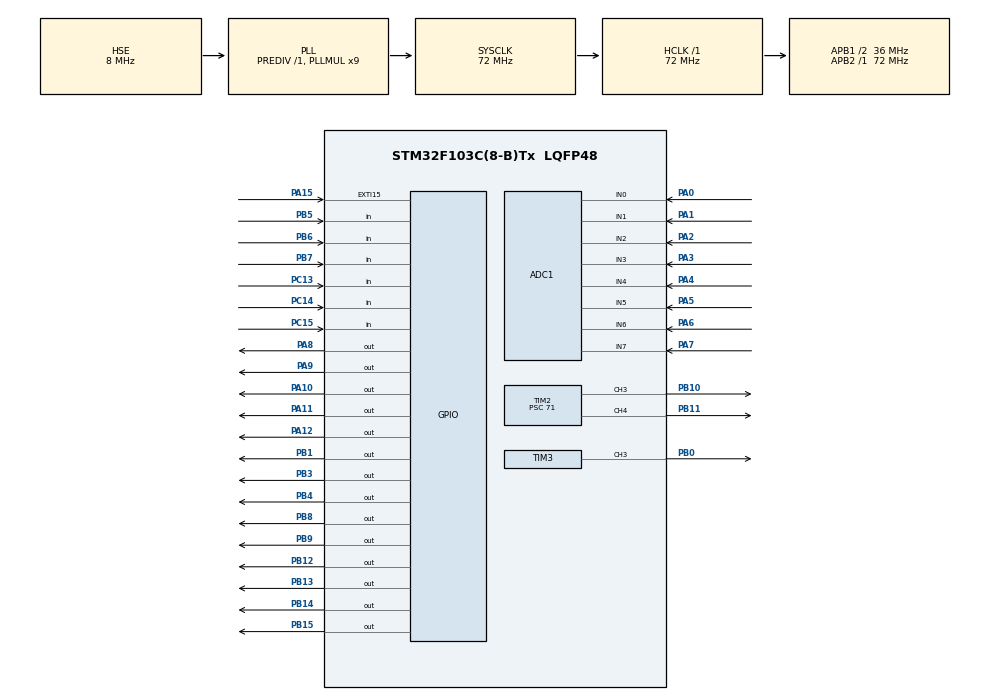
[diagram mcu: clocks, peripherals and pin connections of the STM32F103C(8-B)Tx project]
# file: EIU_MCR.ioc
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ADC1.Channel-0\#ChannelRegularConversion=ADC_CHANNEL_0
ADC1.Channel-1\#ChannelRegularConversion=ADC_CHANNEL_1
ADC1.Channel-2\#ChannelRegularConversion=ADC_CHANNEL_2
ADC1.Channel-3\#ChannelRegularConversion=ADC_CHANNEL_3
ADC1.Channel-4\#ChannelRegularConversion=ADC_CHANNEL_4
ADC1.Channel-5\#ChannelRegularConversion=ADC_CHANNEL_5
ADC1.Channel-6\#ChannelRegularConversion=ADC_CHANNEL_6
ADC1.Channel-7\#ChannelRegularConversion=ADC_CHANNEL_7
ADC1.ContinuousConvMode=ENABLE
ADC1.NbrOfConversion=8
ADC1.NbrOfConversionFlag=1
ADC1.Rank-0\#ChannelRegularConversion=1
ADC1.Rank-1\#ChannelRegularConversion=2
ADC1.Rank-2\#ChannelRegularConversion=3
ADC1.Rank-3\#ChannelRegularConversion=4
ADC1.Rank-4\#ChannelRegularConversion=5
ADC1.Rank-5\#ChannelRegularConversion=6
ADC1.Rank-6\#ChannelRegularConversion=7
ADC1.Rank-7\#ChannelRegularConversion=8
ADC1.SamplingTime-0\#ChannelRegularConversion=ADC_SAMPLETIME_239CYCLES_5
ADC1.SamplingTime-1\#ChannelRegularConversion=ADC_SAMPLETIME_239CYCLES_5
ADC1.SamplingTime-2\#ChannelRegularConversion=ADC_SAMPLETIME_239CYCLES_5
ADC1.SamplingTime-3\#ChannelRegularConversion=ADC_SAMPLETIME_239CYCLES_5
ADC1.SamplingTime-4\#ChannelRegularConversion=ADC_SAMPLETIME_239CYCLES_5
ADC1.SamplingTime-5\#ChannelRegularConversion=ADC_SAMPLETIME_239CYCLES_5
ADC1.SamplingTime-6\#ChannelRegularConversion=ADC_SAMPLETIME_239CYCLES_5
ADC1.SamplingTime-7\#ChannelRegularConversion=ADC_SAMPLETIME_239CYCLES_5
ADC1.master=1
Dma.ADC1.0.Direction=DMA_PERIPH_TO_MEMORY
Dma.ADC1.0.Instance=DMA1_Channel1
Dma.ADC1.0.MemDataAlignment=DMA_MDATAALIGN_HALFWORD
Dma.ADC1.0.MemInc=DMA_MINC_ENABLE
Dma.ADC1.0.Mode=DMA_CIRCULAR
Dma.ADC1.0.PeriphDataAlignment=DMA_PDATAALIGN_HALFWORD
Dma.ADC1.0.PeriphInc=DMA_PINC_DISABLE
Dma.ADC1.0.Priority=DMA_PRIORITY_MEDIUM
Dma.Request0=ADC1
Mcu.Family=STM32F1
Mcu.Name=STM32F103C(8-B)Tx
Mcu.Package=LQFP48
NVIC.DMA1_Channel1_IRQn=true\:0\:0\:false\:false\:true\:false\:true\:true
NVIC.EXTI15_10_IRQn=true\:1\:0\:true\:false\:true\:true\:true\:true
NVIC.PriorityGroup=NVIC_PRIORITYGROUP_4
NVIC.TIM1_UP_IRQn=true\:1\:0\:true\:false\:true\:true\:true\:true
PA0-WKUP.GPIO_Mode=GPIO_MODE_ANALOG
PA0-WKUP.Signal=ADCx_IN0
PA1.GPIO_Mode=GPIO_MODE_ANALOG
PA1.Signal=ADCx_IN1
PA10.GPIO_ModeDefaultOutputPP=GPIO_MODE_OUTPUT_PP
PA10.GPIO_Speed=GPIO_SPEED_FREQ_MEDIUM
PA10.PinState=GPIO_PIN_RESET
PA10.Signal=GPIO_Output
PA11.GPIO_Speed=GPIO_SPEED_FREQ_MEDIUM
PA11.Signal=GPIO_Output
PA12.GPIO_ModeDefaultOutputPP=GPIO_MODE_OUTPUT_PP
PA12.GPIO_PuPd=GPIO_NOPULL
PA12.Signal=GPIO_Output
PA13.Mode=Serial_Wire
PA13.Signal=SYS_JTMS-SWDIO
PA14.Mode=Serial_Wire
PA14.Signal=SYS_JTCK-SWCLK
PA15.GPIO_ModeDefaultEXTI=GPIO_MODE_IT_RISING_FALLING
PA15.GPIO_PuPd=GPIO_PULLUP
PA15.Signal=GPXTI15
PA2.GPIO_Mode=GPIO_MODE_ANALOG
PA2.Signal=ADCx_IN2
PA3.GPIO_Mode=GPIO_MODE_ANALOG
PA3.Signal=ADCx_IN3
PA4.GPIO_Mode=GPIO_MODE_ANALOG
PA4.Signal=ADCx_IN4
PA5.GPIO_Mode=GPIO_MODE_ANALOG
PA5.Signal=ADCx_IN5
PA6.GPIO_Mode=GPIO_MODE_ANALOG
PA6.Signal=ADCx_IN6
PA7.GPIO_Mode=GPIO_MODE_ANALOG
PA7.Signal=ADCx_IN7
PA8.GPIO_ModeDefaultOutputPP=GPIO_MODE_OUTPUT_PP
PA8.GPIO_PuPd=GPIO_NOPULL
PA8.GPIO_Speed=GPIO_SPEED_FREQ_LOW
PA8.PinState=GPIO_PIN_RESET
PA8.Signal=GPIO_Output
PA9.GPIO_PuPd=GPIO_NOPULL
PA9.Signal=GPIO_Output
PB0.Signal=S_TIM3_CH3
PB1.GPIO_Speed=GPIO_SPEED_FREQ_MEDIUM
PB1.Signal=GPIO_Output
PB10.Signal=S_TIM2_CH3
PB11.Signal=S_TIM2_CH4
PB12.GPIO_PuPd=GPIO_PULLDOWN
PB12.GPIO_Speed=GPIO_SPEED_FREQ_MEDIUM
PB12.Signal=GPIO_Output
PB13.GPIO_PuPd=GPIO_PULLDOWN
PB13.GPIO_Speed=GPIO_SPEED_FREQ_MEDIUM
PB13.PinState=GPIO_PIN_RESET
PB13.Signal=GPIO_Output
PB14.GPIO_PuPd=GPIO_PULLDOWN
PB14.GPIO_Speed=GPIO_SPEED_FREQ_MEDIUM
PB14.PinState=GPIO_PIN_RESET
PB14.Signal=GPIO_Output
PB15.GPIO_ModeDefaultOutputPP=GPIO_MODE_OUTPUT_PP
PB15.GPIO_PuPd=GPIO_PULLDOWN
PB15.Signal=GPIO_Output
PB3.GPIO_PuPd=GPIO_PULLDOWN
PB3.Signal=GPIO_Output
PB4.GPIO_Speed=GPIO_SPEED_FREQ_MEDIUM
PB4.Signal=GPIO_Output
PB5.GPIO_Mode=GPIO_MODE_INPUT
PB5.GPIO_PuPd=GPIO_PULLUP
PB5.Signal=GPIO_Input
PB6.GPIO_PuPd=GPIO_PULLUP
PB6.Signal=GPIO_Input
PB7.GPIO_PuPd=GPIO_PULLUP
PB7.Signal=GPIO_Input
PB8.GPIO_PuPd=GPIO_PULLDOWN
PB8.GPIO_Speed=GPIO_SPEED_FREQ_MEDIUM
PB8.PinState=GPIO_PIN_RESET
PB8.Signal=GPIO_Output
PB9.GPIO_PuPd=GPIO_PULLDOWN
PB9.GPIO_Speed=GPIO_SPEED_FREQ_MEDIUM
PB9.Signal=GPIO_Output
PC13-TAMPER-RTC.GPIO_Mode=GPIO_MODE_INPUT
PC13-TAMPER-RTC.GPIO_PuPd=GPIO_PULLUP
PC13-TAMPER-RTC.Signal=GPIO_Input
PC14-OSC32_IN.GPIO_Mode=GPIO_MODE_INPUT
PC14-OSC32_IN.GPIO_PuPd=GPIO_PULLUP
PC14-OSC32_IN.Signal=GPIO_Input
PC15-OSC32_OUT.GPIO_Mode=GPIO_MODE_INPUT
PC15-OSC32_OUT.GPIO_PuPd=GPIO_PULLUP
PC15-OSC32_OUT.Signal=GPIO_Input
PD0-OSC_IN.Mode=HSE-External-Oscillator
PD0-OSC_IN.Signal=RCC_OSC_IN
PD1-OSC_OUT.Mode=HSE-External-Oscillator
PD1-OSC_OUT.Signal=RCC_OSC_OUT
ProjectManager.HeapSize=0x200
ProjectManager.StackSize=0x400
ProjectManager.TargetToolchain=MDK-ARM V5.27
RCC.ADCPresc=RCC_ADCPCLK2_DIV6
RCC.AHBFreq_Value=72000000
RCC.APB1CLKDivider=RCC_HCLK_DIV2
RCC.APB1Freq_Value=36000000
RCC.APB1TimFreq_Value=72000000
RCC.APB2Freq_Value=72000000
RCC.APB2TimFreq_Value=72000000
RCC.HCLKFreq_Value=72000000
RCC.PLLMUL=RCC_PLL_MUL9
RCC.PLLSourceVirtual=RCC_PLLSOURCE_HSE
RCC.SYSCLKFreq_VALUE=72000000
RCC.SYSCLKSource=RCC_SYSCLKSOURCE_PLLCLK
RCC.USBFreq_Value=72000000
SH.ADCx_IN0.0=ADC1_IN0,IN0
SH.ADCx_IN1.0=ADC1_IN1,IN1
SH.ADCx_IN2.0=ADC1_IN2,IN2
SH.ADCx_IN3.0=ADC1_IN3,IN3
SH.ADCx_IN4.0=ADC1_IN4,IN4
SH.ADCx_IN5.0=ADC1_IN5,IN5
SH.ADCx_IN6.0=ADC1_IN6,IN6
SH.ADCx_IN7.0=ADC1_IN7,IN7
SH.S_TIM2_CH3.0=TIM2_CH3,PWM Generation3 CH3
SH.S_TIM2_CH4.0=TIM2_CH4,PWM Generation4 CH4
SH.S_TIM3_CH3.0=TIM3_CH3,PWM Generation3 CH3
TIM1.Prescaler=71
TIM2.Channel-PWM\ Generation3\ CH3=TIM_CHANNEL_3
TIM2.Channel-PWM\ Generation4\ CH4=TIM_CHANNEL_4
TIM2.OCFastMode_PWM-PWM\ Generation3\ CH3=TIM_OCFAST_ENABLE
TIM2.OCFastMode_PWM-PWM\ Generation4\ CH4=TIM_OCFAST_ENABLE
TIM2.Period=999
TIM2.Prescaler=71
TIM3.Channel-PWM\ Generation3\ CH3=TIM_CHANNEL_3
TIM3.CounterMode=TIM_COUNTERMODE_UP
TIM3.OCFastMode_PWM-PWM\ Generation3\ CH3=TIM_OCFAST_DISABLE
TIM3.Period=19999
TIM3.Prescaler=35
TIM4.Prescaler=71
VP_TIM1_VS_ClockSourceINT.Mode=Internal
VP_TIM4_VS_ClockSourceINT.Mode=Internal
board=custom

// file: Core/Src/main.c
/* USER CODE BEGIN Header */
/**
  ******************************************************************************
  * @file           : main.c
  * @brief          : Main program body
  ******************************************************************************
  * @attention
  *
  * <h2><center>&copy; Copyright (c) 2024 STMicroelectronics.
  * All rights reserved.</center></h2>
  *
  * This software component is licensed by ST under BSD 3-Clause license,
  * the "License"; You may not use this file except in compliance with the
  * License. You may obtain a copy of the License at:
  *                        opensource.org/licenses/BSD-3-Clause
  *
  ******************************************************************************
  */
/* USER CODE END Header */
#include "main.h"

/* USER CODE BEGIN Includes */
#include "robot.h"

/* USER CODE END Includes */

ADC_HandleTypeDef hadc1;
DMA_HandleTypeDef hdma_adc1;

TIM_HandleTypeDef htim1;
TIM_HandleTypeDef htim2;
TIM_HandleTypeDef htim3;
TIM_HandleTypeDef htim4;

void SystemClock_Config(void);
static void MX_GPIO_Init(void);
static void MX_DMA_Init(void);
static void MX_TIM3_Init(void);
static void MX_TIM2_Init(void);
static void MX_TIM1_Init(void);
static void MX_TIM4_Init(void);
static void MX_ADC1_Init(void);

/* USER CODE BEGIN 0 */
Robot MCR_robot;
TIM_HandleTypeDef *htim[] = {&htim1, &htim2, &htim3, &htim4};
void HAL_TIM_PeriodElapsedCallback(TIM_HandleTypeDef *htim)
{
 timer_handle(&MCR_robot);
}
/* USER CODE END 0 */

int main(void)

{

  /* MCU Configuration--------------------------------------------------------*/

  /* Reset of all peripherals, Initializes the Flash interface and the Systick. */
  HAL_Init();

  /* Configure the system clock */
  SystemClock_Config();

  /* Initialize all configured peripherals */
  MX_GPIO_Init();
  MX_DMA_Init();
  MX_TIM3_Init();
  MX_TIM2_Init();
  MX_TIM1_Init();
  MX_TIM4_Init();
  MX_ADC1_Init();
  /* USER CODE BEGIN 2 */
  robot_init(&MCR_robot, &hadc1, &hdma_adc1, htim);
	HAL_TIM_Base_Start_IT(&htim1);
  /* USER CODE END 2 */

  /* Infinite loop */
  while (1)
  {
    /* USER CODE BEGIN 3 */
		loop(&MCR_robot);
	  //handle(&servo, 0);
  }
  /* USER CODE END 3 */
}

void SystemClock_Config(void)
{
  RCC_OscInitTypeDef RCC_OscInitStruct = {0};
  RCC_ClkInitTypeDef RCC_ClkInitStruct = {0};
  RCC_PeriphCLKInitTypeDef PeriphClkInit = {0};

  /** Initializes the RCC Oscillators according to the specified parameters
  * in the RCC_OscInitTypeDef structure.
  */
  RCC_OscInitStruct.OscillatorType = RCC_OSCILLATORTYPE_HSE;
  RCC_OscInitStruct.HSEState = RCC_HSE_ON;
  RCC_OscInitStruct.HSEPredivValue = RCC_HSE_PREDIV_DIV1;
  RCC_OscInitStruct.HSIState = RCC_HSI_ON;
  RCC_OscInitStruct.PLL.PLLState = RCC_PLL_ON;
  RCC_OscInitStruct.PLL.PLLSource = RCC_PLLSOURCE_HSE;
  RCC_OscInitStruct.PLL.PLLMUL = RCC_PLL_MUL9;
  if (HAL_RCC_OscConfig(&RCC_OscInitStruct) != HAL_OK)
  {
    Error_Handler();
  }
  /** Initializes the CPU, AHB and APB buses clocks
  */
  RCC_ClkInitStruct.ClockType = RCC_CLOCKTYPE_HCLK|RCC_CLOCKTYPE_SYSCLK
                              |RCC_CLOCKTYPE_PCLK1|RCC_CLOCKTYPE_PCLK2;
  RCC_ClkInitStruct.SYSCLKSource = RCC_SYSCLKSOURCE_PLLCLK;
  RCC_ClkInitStruct.AHBCLKDivider = RCC_SYSCLK_DIV1;
  RCC_ClkInitStruct.APB1CLKDivider = RCC_HCLK_DIV2;
  RCC_ClkInitStruct.APB2CLKDivider = RCC_HCLK_DIV1;

  if (HAL_RCC_ClockConfig(&RCC_ClkInitStruct, FLASH_LATENCY_2) != HAL_OK)
  {
    Error_Handler();
  }
  PeriphClkInit.PeriphClockSelection = RCC_PERIPHCLK_ADC;
  PeriphClkInit.AdcClockSelection = RCC_ADCPCLK2_DIV6;
  if (HAL_RCCEx_PeriphCLKConfig(&PeriphClkInit) != HAL_OK)
  {
    Error_Handler();
  }
}

static void MX_ADC1_Init(void)
{

  ADC_ChannelConfTypeDef sConfig = {0};

  /** Common config
  */
  hadc1.Instance = ADC1;
  hadc1.Init.ScanConvMode = ADC_SCAN_ENABLE;
  hadc1.Init.ContinuousConvMode = ENABLE;
  hadc1.Init.DiscontinuousConvMode = DISABLE;
  hadc1.Init.ExternalTrigConv = ADC_SOFTWARE_START;
  hadc1.Init.DataAlign = ADC_DATAALIGN_RIGHT;
  hadc1.Init.NbrOfConversion = 8;
  if (HAL_ADC_Init(&hadc1) != HAL_OK)
  {
    Error_Handler();
  }
  /** Configure Regular Channel
  */
  sConfig.Channel = ADC_CHANNEL_0;
  sConfig.Rank = ADC_REGULAR_RANK_1;
  sConfig.SamplingTime = ADC_SAMPLETIME_239CYCLES_5;
  if (HAL_ADC_ConfigChannel(&hadc1, &sConfig) != HAL_OK)
  {
    Error_Handler();
  }
  /** Configure Regular Channel
  */
  sConfig.Channel = ADC_CHANNEL_1;
  sConfig.Rank = ADC_REGULAR_RANK_2;
  if (HAL_ADC_ConfigChannel(&hadc1, &sConfig) != HAL_OK)
  {
    Error_Handler();
  }
  /** Configure Regular Channel
  */
  sConfig.Channel = ADC_CHANNEL_2;
  sConfig.Rank = ADC_REGULAR_RANK_3;
  if (HAL_ADC_ConfigChannel(&hadc1, &sConfig) != HAL_OK)
  {
    Error_Handler();
  }
  /** Configure Regular Channel
  */
  sConfig.Channel = ADC_CHANNEL_3;
  sConfig.Rank = ADC_REGULAR_RANK_4;
  if (HAL_ADC_ConfigChannel(&hadc1, &sConfig) != HAL_OK)
  {
    Error_Handler();
  }
  /** Configure Regular Channel
  */
  sConfig.Channel = ADC_CHANNEL_4;
  sConfig.Rank = ADC_REGULAR_RANK_5;
  if (HAL_ADC_ConfigChannel(&hadc1, &sConfig) != HAL_OK)
  {
    Error_Handler();
  }
  /** Configure Regular Channel
  */
  sConfig.Channel = ADC_CHANNEL_5;
  sConfig.Rank = ADC_REGULAR_RANK_6;
  if (HAL_ADC_ConfigChannel(&hadc1, &sConfig) != HAL_OK)
  {
    Error_Handler();
  }
  /** Configure Regular Channel
  */
  sConfig.Channel = ADC_CHANNEL_6;
  sConfig.Rank = ADC_REGULAR_RANK_7;
  if (HAL_ADC_ConfigChannel(&hadc1, &sConfig) != HAL_OK)
  {
    Error_Handler();
  }
  /** Configure Regular Channel
  */
  sConfig.Channel = ADC_CHANNEL_7;
  sConfig.Rank = ADC_REGULAR_RANK_8;
  if (HAL_ADC_ConfigChannel(&hadc1, &sConfig) != HAL_OK)
  {
    Error_Handler();
  }

}

static void MX_TIM1_Init(void)
{

  TIM_ClockConfigTypeDef sClockSourceConfig = {0};
  TIM_MasterConfigTypeDef sMasterConfig = {0};

  htim1.Instance = TIM1;
  htim1.Init.Prescaler = 71;
  htim1.Init.CounterMode = TIM_COUNTERMODE_UP;
  htim1.Init.Period = 999;
  htim1.Init.ClockDivision = TIM_CLOCKDIVISION_DIV1;
  htim1.Init.RepetitionCounter = 0;
  htim1.Init.AutoReloadPreload = TIM_AUTORELOAD_PRELOAD_DISABLE;
  if (HAL_TIM_Base_Init(&htim1) != HAL_OK)
  {
    Error_Handler();
  }
  sClockSourceConfig.ClockSource = TIM_CLOCKSOURCE_INTERNAL;
  if (HAL_TIM_ConfigClockSource(&htim1, &sClockSourceConfig) != HAL_OK)
  {
    Error_Handler();
  }
  sMasterConfig.MasterOutputTrigger = TIM_TRGO_RESET;
  sMasterConfig.MasterSlaveMode = TIM_MASTERSLAVEMODE_DISABLE;
  if (HAL_TIMEx_MasterConfigSynchronization(&htim1, &sMasterConfig) != HAL_OK)
  {
    Error_Handler();
  }

}

static void MX_TIM2_Init(void)
{

  TIM_MasterConfigTypeDef sMasterConfig = {0};
  TIM_OC_InitTypeDef sConfigOC = {0};

  htim2.Instance = TIM2;
  htim2.Init.Prescaler = 71;
  htim2.Init.CounterMode = TIM_COUNTERMODE_UP;
  htim2.Init.Period = 999;
  htim2.Init.ClockDivision = TIM_CLOCKDIVISION_DIV1;
  htim2.Init.AutoReloadPreload = TIM_AUTORELOAD_PRELOAD_DISABLE;
  if (HAL_TIM_PWM_Init(&htim2) != HAL_OK)
  {
    Error_Handler();
  }
  sMasterConfig.MasterOutputTrigger = TIM_TRGO_RESET;
  sMasterConfig.MasterSlaveMode = TIM_MASTERSLAVEMODE_DISABLE;
  if (HAL_TIMEx_MasterConfigSynchronization(&htim2, &sMasterConfig) != HAL_OK)
  {
    Error_Handler();
  }
  sConfigOC.OCMode = TIM_OCMODE_PWM1;
  sConfigOC.Pulse = 0;
  sConfigOC.OCPolarity = TIM_OCPOLARITY_HIGH;
  sConfigOC.OCFastMode = TIM_OCFAST_ENABLE;
  if (HAL_TIM_PWM_ConfigChannel(&htim2, &sConfigOC, TIM_CHANNEL_3) != HAL_OK)
  {
    Error_Handler();
  }
  if (HAL_TIM_PWM_ConfigChannel(&htim2, &sConfigOC, TIM_CHANNEL_4) != HAL_OK)
  {
    Error_Handler();
  }
  HAL_TIM_MspPostInit(&htim2);

}

static void MX_TIM3_Init(void)
{

  TIM_MasterConfigTypeDef sMasterConfig = {0};
  TIM_OC_InitTypeDef sConfigOC = {0};

  htim3.Instance = TIM3;
  htim3.Init.Prescaler = 35;
  htim3.Init.CounterMode = TIM_COUNTERMODE_UP;
  htim3.Init.Period = 19999;
  htim3.Init.ClockDivision = TIM_CLOCKDIVISION_DIV1;
  htim3.Init.AutoReloadPreload = TIM_AUTORELOAD_PRELOAD_DISABLE;
  if (HAL_TIM_PWM_Init(&htim3) != HAL_OK)
  {
    Error_Handler();
  }
  sMasterConfig.MasterOutputTrigger = TIM_TRGO_RESET;
  sMasterConfig.MasterSlaveMode = TIM_MASTERSLAVEMODE_DISABLE;
  if (HAL_TIMEx_MasterConfigSynchronization(&htim3, &sMasterConfig) != HAL_OK)
  {
    Error_Handler();
  }
  sConfigOC.OCMode = TIM_OCMODE_PWM1;
  sConfigOC.Pulse = 0;
  sConfigOC.OCPolarity = TIM_OCPOLARITY_HIGH;
  sConfigOC.OCFastMode = TIM_OCFAST_DISABLE;
  if (HAL_TIM_PWM_ConfigChannel(&htim3, &sConfigOC, TIM_CHANNEL_3) != HAL_OK)
  {
    Error_Handler();
  }
  HAL_TIM_MspPostInit(&htim3);

}

static void MX_TIM4_Init(void)
{

  TIM_ClockConfigTypeDef sClockSourceConfig = {0};
  TIM_MasterConfigTypeDef sMasterConfig = {0};

  htim4.Instance = TIM4;
  htim4.Init.Prescaler = 71;
  htim4.Init.CounterMode = TIM_COUNTERMODE_UP;
  htim4.Init.Period = 65535;
  htim4.Init.ClockDivision = TIM_CLOCKDIVISION_DIV1;
  htim4.Init.AutoReloadPreload = TIM_AUTORELOAD_PRELOAD_DISABLE;
  if (HAL_TIM_Base_Init(&htim4) != HAL_OK)
  {
    Error_Handler();
  }
  sClockSourceConfig.ClockSource = TIM_CLOCKSOURCE_INTERNAL;
  if (HAL_TIM_ConfigClockSource(&htim4, &sClockSourceConfig) != HAL_OK)
  {
    Error_Handler();
  }
  sMasterConfig.MasterOutputTrigger = TIM_TRGO_RESET;
  sMasterConfig.MasterSlaveMode = TIM_MASTERSLAVEMODE_DISABLE;
  if (HAL_TIMEx_MasterConfigSynchronization(&htim4, &sMasterConfig) != HAL_OK)
  {
    Error_Handler();
  }

}

static void MX_DMA_Init(void)
{

  /* DMA controller clock enable */
  __HAL_RCC_DMA1_CLK_ENABLE();

  /* DMA interrupt init */
  /* DMA1_Channel1_IRQn interrupt configuration */
  HAL_NVIC_SetPriority(DMA1_Channel1_IRQn, 0, 0);
  HAL_NVIC_EnableIRQ(DMA1_Channel1_IRQn);

}

static void MX_GPIO_Init(void)
{
  GPIO_InitTypeDef GPIO_InitStruct = {0};

  /* GPIO Ports Clock Enable */
  __HAL_RCC_GPIOC_CLK_ENABLE();
  __HAL_RCC_GPIOD_CLK_ENABLE();
  __HAL_RCC_GPIOA_CLK_ENABLE();
  __HAL_RCC_GPIOB_CLK_ENABLE();

  /*Configure GPIO pin Output Level */
  HAL_GPIO_WritePin(GPIOB, GPIO_PIN_1|GPIO_PIN_12|GPIO_PIN_13|GPIO_PIN_14
                          |GPIO_PIN_15|GPIO_PIN_3|GPIO_PIN_4|GPIO_PIN_8
                          |GPIO_PIN_9, GPIO_PIN_RESET);

  /*Configure GPIO pin Output Level */
  HAL_GPIO_WritePin(GPIOA, GPIO_PIN_8|GPIO_PIN_9|GPIO_PIN_10|GPIO_PIN_11
                          |GPIO_PIN_12, GPIO_PIN_RESET);

  /*Configure GPIO pins : PC13 PC14 PC15 */
  GPIO_InitStruct.Pin = GPIO_PIN_13|GPIO_PIN_14|GPIO_PIN_15;
  GPIO_InitStruct.Mode = GPIO_MODE_INPUT;
  GPIO_InitStruct.Pull = GPIO_PULLUP;
  HAL_GPIO_Init(GPIOC, &GPIO_InitStruct);

  /*Configure GPIO pins : PB1 PB4 */
  GPIO_InitStruct.Pin = GPIO_PIN_1|GPIO_PIN_4;
  GPIO_InitStruct.Mode = GPIO_MODE_OUTPUT_PP;
  GPIO_InitStruct.Pull = GPIO_NOPULL;
  GPIO_InitStruct.Speed = GPIO_SPEED_FREQ_MEDIUM;
  HAL_GPIO_Init(GPIOB, &GPIO_InitStruct);

  /*Configure GPIO pins : PB12 PB13 PB14 PB8
                           PB9 */
  GPIO_InitStruct.Pin = GPIO_PIN_12|GPIO_PIN_13|GPIO_PIN_14|GPIO_PIN_8
                          |GPIO_PIN_9;
  GPIO_InitStruct.Mode = GPIO_MODE_OUTPUT_PP;
  GPIO_InitStruct.Pull = GPIO_PULLDOWN;
  GPIO_InitStruct.Speed = GPIO_SPEED_FREQ_MEDIUM;
  HAL_GPIO_Init(GPIOB, &GPIO_InitStruct);

  /*Configure GPIO pins : PB15 PB3 */
  GPIO_InitStruct.Pin = GPIO_PIN_15|GPIO_PIN_3;
  GPIO_InitStruct.Mode = GPIO_MODE_OUTPUT_PP;
  GPIO_InitStruct.Pull = GPIO_PULLDOWN;
  GPIO_InitStruct.Speed = GPIO_SPEED_FREQ_LOW;
  HAL_GPIO_Init(GPIOB, &GPIO_InitStruct);

  /*Configure GPIO pins : PA8 PA9 PA12 */
  GPIO_InitStruct.Pin = GPIO_PIN_8|GPIO_PIN_9|GPIO_PIN_12;
  GPIO_InitStruct.Mode = GPIO_MODE_OUTPUT_PP;
  GPIO_InitStruct.Pull = GPIO_NOPULL;
  GPIO_InitStruct.Speed = GPIO_SPEED_FREQ_LOW;
  HAL_GPIO_Init(GPIOA, &GPIO_InitStruct);

  /*Configure GPIO pins : PA10 PA11 */
  GPIO_InitStruct.Pin = GPIO_PIN_10|GPIO_PIN_11;
  GPIO_InitStruct.Mode = GPIO_MODE_OUTPUT_PP;
  GPIO_InitStruct.Pull = GPIO_NOPULL;
  GPIO_InitStruct.Speed = GPIO_SPEED_FREQ_MEDIUM;
  HAL_GPIO_Init(GPIOA, &GPIO_InitStruct);

  /*Configure GPIO pin : PA15 */
  GPIO_InitStruct.Pin = GPIO_PIN_15;
  GPIO_InitStruct.Mode = GPIO_MODE_IT_RISING_FALLING;
  GPIO_InitStruct.Pull = GPIO_PULLUP;
  HAL_GPIO_Init(GPIOA, &GPIO_InitStruct);

  /*Configure GPIO pins : PB5 PB6 PB7 */
  GPIO_InitStruct.Pin = GPIO_PIN_5|GPIO_PIN_6|GPIO_PIN_7;
  GPIO_InitStruct.Mode = GPIO_MODE_INPUT;
  GPIO_InitStruct.Pull = GPIO_PULLUP;
  HAL_GPIO_Init(GPIOB, &GPIO_InitStruct);

  /* EXTI interrupt init*/
  HAL_NVIC_SetPriority(EXTI15_10_IRQn, 1, 0);
  HAL_NVIC_EnableIRQ(EXTI15_10_IRQn);

}

void Error_Handler(void)
{
  __disable_irq();
  while (1)
  {
  }
}

/************************ (C) COPYRIGHT STMicroelectronics *****END OF FILE****/
